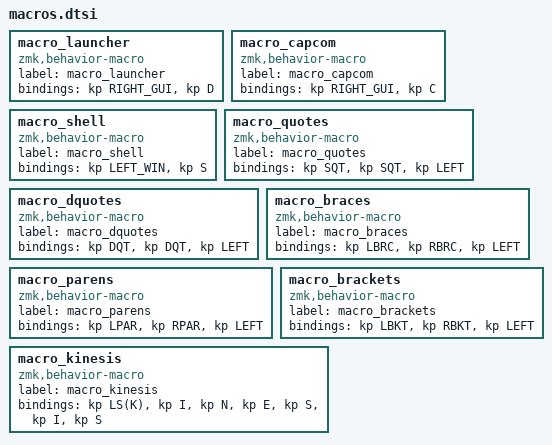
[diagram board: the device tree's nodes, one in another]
macro_launcher: macro_launcher{
compatible = "zmk,behavior-macro";
label = "macro_launcher";
#binding-cells = <0>;
bindings = <&kp RIGHT_GUI>, <&kp D>;
};
macro_capcom: macro_capcom{
compatible = "zmk,behavior-macro";
label = "macro_capcom";
#binding-cells = <0>;
bindings = <&kp RIGHT_GUI>, <&kp C>;
};
macro_shell: macro_shell{
compatible = "zmk,behavior-macro";
label = "macro_shell";
#binding-cells = <0>;
bindings = <&kp LEFT_WIN>, <&kp S>;
};
macro_quotes: macro_quotes{
compatible = "zmk,behavior-macro";
label = "macro_quotes";
#binding-cells = <0>;
bindings = <&kp SQT>, <&kp SQT>, <&kp LEFT>;
};
macro_dquotes: macro_dquotes{
compatible = "zmk,behavior-macro";
label = "macro_dquotes";
#binding-cells = <0>;
bindings = <&kp DQT>, <&kp DQT>, <&kp LEFT>;
};
macro_braces: macro_braces{
compatible = "zmk,behavior-macro";
label = "macro_braces";
#binding-cells = <0>;
bindings = <&kp LBRC>, <&kp RBRC>, <&kp LEFT>;
};
macro_parens: macro_parens{
compatible = "zmk,behavior-macro";
label = "macro_parens";
#binding-cells = <0>;
bindings = <&kp LPAR>, <&kp RPAR>, <&kp LEFT>;
};
macro_brackets: macro_brackets{
compatible = "zmk,behavior-macro";
label = "macro_brackets";
#binding-cells = <0>;
bindings = <&kp LBKT>, <&kp RBKT>, <&kp LEFT>;
};
macro_kinesis: macro_kinesis{
compatible = "zmk,behavior-macro";
label = "macro_kinesis";
#binding-cells = <0>;
bindings = <&kp LS(K)>, <&kp I>, <&kp N>, <&kp E>, <&kp S>, <&kp I>, <&kp S>;
};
